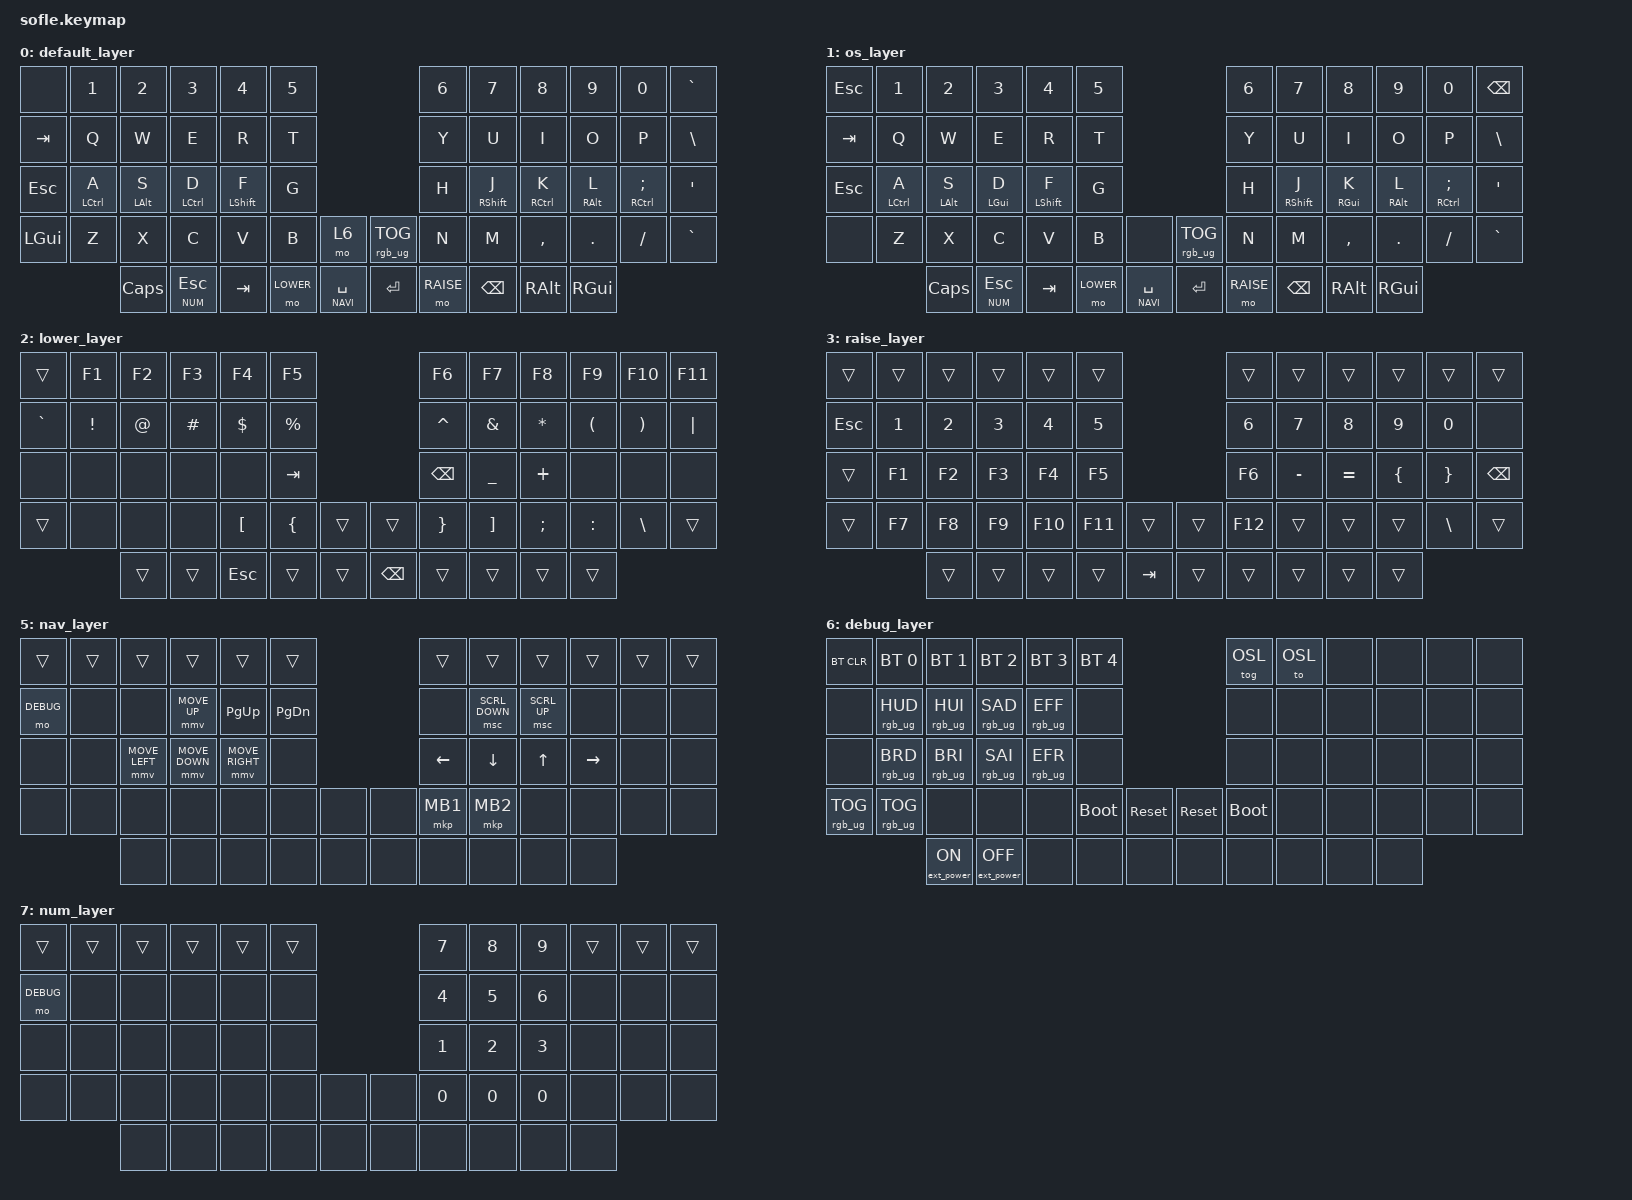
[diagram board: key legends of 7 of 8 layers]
/*
 * Copyright (c) 2020 The ZMK Contributors
 *
 * SPDX-License-Identifier: MIT
 */

#include "zmk-helpers/helper.h"

// Source desired key-position labels

#include "zmk-helpers/key-labels/sofle.h"

// tap windows for ctl alt and gui

#define HM_TAPPING_TERM 200
#define HM_TAPPING_REPEAT 210

// quick tapping for shift

#define HM_TAPPING_TERM_FAST 200
#define HM_PRIOR_IDLE 70
#define BASE 0
#define OSL 1
#define LOWER 2
#define RAISE 3
#define ADJUST 4
#define NAVI   5
#define DEBUG  6
#define NUM    7

// https://github.com/urob/zmk-config/tree/main#timeless-homerow-mods

#define KEYS_L LN5 LN4 LN3 LN2 LN1 LN0 LT0 LT1 LT2 LT3 LT4 LT5 LM0 LM1 LM2 LM3 LM4 LM5 LB0 LB1 LB2 LB3 LB4 LB5  // left hand
#define KEYS_R RN0 RN1 RN2 RN3 RN4 RN5 RT0 RT1 RT2 RT3 RT4 RT5 RM0 RM1 RM2 RM3 RM4 RM5 RB0 RB1 RB2 RB3 RB4 RB5  // right hand

#define THUMBS LH1 LH0 RH0 RH1
#define KEYS_T LH1 LH0 RH0 RH1

#include <behaviors.dtsi>
#include <dt-bindings/zmk/bt.h>
#include <dt-bindings/zmk/ext_power.h>
#include <dt-bindings/zmk/keys.h>
#include <dt-bindings/zmk/pointing.h>
#include <dt-bindings/zmk/pointing.h>
#include <dt-bindings/zmk/pointing.h>
#include <dt-bindings/zmk/rgb.h>

/ {
    // Activate ADJUST layer by pressing raise and lower

    behaviors {
        // Positional Homerow mods
        // Homerow mods that prevent accidental activations when rolling keys,
        // such as when typing `st` or `ne` on colemak-dh layouts or `as` on
        // qwerty.
        //
        // Works by only allowing a mod to activate within tapping-term if
        // it's on the opposite side of the keyboard or on the same side thumb
        // keys.
        // Further optimization using urob's timerless homerow mods method:
        // https://github.com/urob/zmk-config#timeless-homerow-mods

        hm_l: homerow_mods_left {
            compatible = "zmk,behavior-hold-tap";
            #binding-cells = <2>;
            bindings = <&kp>, <&kp>;

            flavor = "balanced";
            tapping-term-ms = <HM_TAPPING_TERM>;
            quick-tap-ms = <200>;                // repeat on tap-into-hold
            require-prior-idle-ms = <HM_PRIOR_IDLE>;
            hold-trigger-key-positions = <KEYS_R KEYS_T>;
            hold-trigger-on-release;
        };

        hm_r: homerow_mods_right {
            compatible = "zmk,behavior-hold-tap";
            #binding-cells = <2>;
            bindings = <&kp>, <&kp>;

            flavor = "balanced";
            tapping-term-ms = <HM_TAPPING_TERM>;
            quick-tap-ms = <200>;
            require-prior-idle-ms = <HM_PRIOR_IDLE>;
            hold-trigger-key-positions = <KEYS_L KEYS_T>;
            hold-trigger-on-release;
        };

        // Positional Homerow mods for shift
        // Use faster tapping term and disable some features that may
        // cause false negatives.

        hm_shift_l: hm_shift_l {
            compatible = "zmk,behavior-hold-tap";
            #binding-cells = <2>;
            bindings = <&kp>, <&kp>;

            //flavor = "balanced";

            flavor = "balanced";
            tapping-term-ms = <HM_TAPPING_TERM_FAST>;
            quick-tap-ms = <200>;
            require-prior-idle-ms = <HM_PRIOR_IDLE>;
            hold-trigger-key-positions = <KEYS_R KEYS_T>;
            hold-trigger-on-release;
        };

        hm_shift_r: hm_shift_r {
            compatible = "zmk,behavior-hold-tap";
            #binding-cells = <2>;
            bindings = <&kp>, <&kp>;

            flavor = "balanced";
            tapping-term-ms = <HM_TAPPING_TERM_FAST>;
            quick-tap-ms = <200>;
            require-prior-idle-ms = <HM_PRIOR_IDLE>;
            hold-trigger-key-positions = <KEYS_L KEYS_T>;

            // for quick tapping; shift+~

            hold-trigger-on-release;
        };

        /*
         * Non-Positional Homerow Mods
         * Used for &mm_grescm_gui behavior on left hand.
         *
         * Usage: &hm LSHFT T
         * Tap: T
         * Tap-Tap-Hold: Repeat T
         * Hold: LSHIFT
         */

        hm: homerow_mods {
            compatible = "zmk,behavior-hold-tap";
            #binding-cells = <2>;
            bindings = <&kp>, <&kp>;

            flavor = "balanced";
            tapping-term-ms = <HM_TAPPING_TERM>;
            quick-tap-ms = <200>;
        };
    };

    conditional_layers {
        compatible = "zmk,conditional-layers";

        adjust_layer {
            if-layers = <LOWER RAISE>;
            then-layer = <ADJUST>;
        };
    };

    keymap {
        compatible = "zmk,keymap";

        default_layer {
            // ------------------------------------------------------------------------------------------------------------
            // |   `   |  1  |  2  |  3   |  4   |  5   |                   |  6   |  7    |  8    |  9   |   0   |       |
            // |  ESC  |  Q  |  W  |  E   |  R   |  T   |                   |  Y   |  U    |  I    |  O   |   P   | BKSPC |
            // |  TAB  |  A  |  S  |  D   |  F   |  G   |                   |  H   |  J    |  K    |  L   |   ;   |   '   |
            // | SHIFT |  Z  |  X  |  C   |  V   |  B   |  MUTE  |  |       |  N   |  M    |  ,    |  .   |   /   | SHIFT |
            //               | GUI | ALT  | CTRL | LOWER|  ENTER |  | SPACE | RAISE| CTRL  | ALT   | GUI  |

            bindings = <
&none     &kp N1         &kp N2        &kp N3         &kp N4               &kp N5                                        &kp N6     &kp N7               &kp N8         &kp N9        &kp N0            &kp GRAVE
&kp TAB   &kp Q          &kp W         &kp E          &kp R                &kp T                                         &kp Y      &kp U                &kp I          &kp O         &kp P             &kp BSLH
&kp ESC   &hm_l LCTRL A  &hm_l LALT S  &hm_l LCTRL D  &hm_shift_l LSHFT F  &kp G                                         &kp H      &hm_shift_r RSHFT J  &hm_r RCTRL K  &hm_r RALT L  &hm_r RCTRL SEMI  &kp SQT
&kp LGUI  &kp Z          &kp X         &kp C          &kp V                &kp B      &mo 6             &rgb_ug RGB_TOG  &kp N      &kp M                &kp COMMA      &kp DOT       &kp FSLH          &kp GRAVE
                         &kp CAPS      &lt NUM ESC    &kp TAB              &mo LOWER  &lt NAVI SPACE    &kp RET          &mo RAISE  &kp BSPC             &kp RALT       &kp RGUI
            >;

            sensor-bindings = <&inc_dec_kp C_VOL_UP C_VOL_DN &inc_dec_kp PG_UP PG_DN>;
        };

        os_layer {
            // ------------------------------------------------------------------------------------------------------------
            // |   `   |  1  |  2  |  3   |  4   |  5   |                   |  6   |  7    |  8    |  9   |   0   |       |
            // |  ESC  |  Q  |  W  |  E   |  R   |  T   |                   |  Y   |  U    |  I    |  O   |   P   | BKSPC |
            // |  TAB  |  A  |  S  |  D   |  F   |  G   |                   |  H   |  J    |  K    |  L   |   ;   |   '   |
            // | SHIFT |  Z  |  X  |  C   |  V   |  B   |  MUTE  |  |       |  N   |  M    |  ,    |  .   |   /   | SHIFT |
            //               | GUI | ALT  | CTRL | LOWER|  ENTER |  | SPACE | RAISE| CTRL  | ALT   | GUI  |

            bindings = <
&kp ESC  &kp N1         &kp N2        &kp N3        &kp N4               &kp N5                                        &kp N6     &kp N7               &kp N8        &kp N9        &kp N0            &kp BSPC
&kp TAB  &kp Q          &kp W         &kp E         &kp R                &kp T                                         &kp Y      &kp U                &kp I         &kp O         &kp P             &kp BSLH
&kp ESC  &hm_l LCTRL A  &hm_l LALT S  &hm_l LGUI D  &hm_shift_l LSHFT F  &kp G                                         &kp H      &hm_shift_r RSHFT J  &hm_r RGUI K  &hm_r RALT L  &hm_r RCTRL SEMI  &kp SQT
&none    &kp Z          &kp X         &kp C         &kp V                &kp B      &none             &rgb_ug RGB_TOG  &kp N      &kp M                &kp COMMA     &kp DOT       &kp FSLH          &kp GRAVE
                        &kp CAPS      &lt NUM ESC   &kp TAB              &mo LOWER  &lt NAVI SPACE    &kp RET          &mo RAISE  &kp BSPC             &kp RALT      &kp RGUI
            >;

            sensor-bindings = <&inc_dec_kp C_VOL_UP C_VOL_DN &inc_dec_kp PG_UP PG_DN>;
        };

        lower_layer {
            // TODO: Some binds are waiting for shifted keycode support.
            // -------------------------------
            // |       |  F1 |  F2 |  F3  |  F4  |  F5  |                   |  F6  |  F7   |  F8   |  F9  |  F10  |  F11  |
            // |   `   |  1  |  2  |  3   |  4   |  5   |                   |  6   |  7    |  8    |  9   |   0   |  F12  |
            // |       |  !  |  @  |  #   |  $   |  %   |                   |  ^   |  &    |  *    |  (   |   )   |   |   |
            // |       |  =  |  -  |  +   |  {   |  }   |        |  |       |  [   |  ]    |  ;    |  :   |   \   |       |
            //               |     |      |      |      |        |  |       |      |       |       |      |

            bindings = <
&trans     &kp F1    &kp F2  &kp F3    &kp F4            &kp F5                         &kp F6           &kp F7     &kp F8     &kp F9     &kp F10   &kp F11
&kp GRAVE  &kp EXCL  &kp AT  &kp HASH  &kp DLLR          &kp PRCNT                      &kp CARET        &kp AMPS   &kp ASTRK  &kp LPAR   &kp RPAR  &kp PIPE
&none      &none     &none   &none     &none             &kp TAB                        &kp BSPC         &kp UNDER  &kp PLUS   &none      &none     &none
&trans     &none     &none   &none     &kp LEFT_BRACKET  &kp LBRC   &trans    &trans    &kp RIGHT_BRACE  &kp RBKT   &kp SEMI   &kp COLON  &kp BSLH  &trans
                     &trans  &trans    &kp ESC           &trans     &trans    &kp BSPC  &trans           &trans     &trans     &trans
            >;

            sensor-bindings = <&inc_dec_kp C_VOL_UP C_VOL_DN &inc_dec_kp PG_UP PG_DN>;
        };

        raise_layer {
            // ------------------------------------------------------------------------------------------------------------
            // | BTCLR | BT1  | BT2  |  BT3  |  BT4  |  BT5 |                |      |      |       |      |       |       |
            // |       | INS  | PSCR | GUI   |       |      |                | PGUP |      |   ^   |      |       |       |
            // |       | ALT  | CTRL | SHIFT |       | CAPS |                | PGDN |   <- |   v   |  ->  |  DEL  | BKSPC |
            // |       | UNDO | CUT  | COPY  | PASTE |      |      |  |      |      |      |       |      |       |       |
            //                |      |       |       |      |      |  |      |      |      |       |      |

            bindings = <
&trans   &trans  &trans  &trans  &trans   &trans                     &trans   &trans     &trans     &trans    &trans    &trans
&kp ESC  &kp N1  &kp N2  &kp N3  &kp N4   &kp N5                     &kp N6   &kp N7     &kp N8     &kp N9    &kp N0    &none
&trans   &kp F1  &kp F2  &kp F3  &kp F4   &kp F5                     &kp F6   &kp MINUS  &kp EQUAL  &kp LBRC  &kp RBRC  &kp BSPC
&trans   &kp F7  &kp F8  &kp F9  &kp F10  &kp F11  &trans    &trans  &kp F12  &trans     &trans     &trans    &kp BSLH  &trans
                 &trans  &trans  &trans   &trans   &kp TAB   &trans  &trans   &trans     &trans     &trans
            >;

            sensor-bindings = <&inc_dec_kp C_VOL_UP C_VOL_DN &inc_dec_kp PG_UP PG_DN>;
        };

        adjust_layer {
            // ----------------------------------------------------------------------------------------------------------------------------
            // | BTCLR  |  BT1    |  BT2    |   BT3   |   BT4   |   BT5   |                  |      |      |       |      |       |       |
            // | moDEBUG| RGB_HUD | RGB_HUI | RGB_SAD | RGB_SAI | RGB_EFF |                  |      |      |       |      |       |       |
            // | EXTPWR | RGB_BRD | RGB_BRI |         |         |         |                  |      |      |       |      |       |       |
            // |        |         |         |         |         |         | RGB_TOG | |      |      |      |       |      |       |       |
            //                    |         |         |         |         |         | |      |      |      |       |      |

            bindings = <
&none            &bt BT_SEL 0     &bt BT_SEL 1       &bt BT_SEL 2     &bt BT_SEL 3  &bt BT_SEL 4                       &tog OSL  &to OSL  &none  &none  &none  &tog OSL
&rgb_ug RGB_HUD  &rgb_ug RGB_HUI  &rgb_ug RGB_SAD    &rgb_ug RGB_EFF  &none         &none                              &none     &none    &none  &none  &none  &none
&rgb_ug RGB_BRD  &rgb_ug RGB_BRI  &rgb_ug RGB_SAI    &rgb_ug RGB_EFR  &none         &none                              &none     &none    &none  &none  &none  &rgb_ug RGB_TOG
&none            &none            &none              &none            &none         &sys_reset    &sys_reset    &none  &none     &none    &none  &none  &none  &ext_power EP_ON
                                  &ext_power EP_OFF  &none            &none         &none         &none         &none  &none     &none    &none
            >;
        };

        nav_layer {
            // ----------------------------------------------------------------------------------------------------------------------------
            // | BTCLR  |  BT1    |  BT2    |   BT3   |   BT4   |   BT5   |                  |      |      |       |      |       |       |
            // | moDEBUG| RGB_HUD | RGB_HUI | RGB_SAD | RGB_SAI | RGB_EFF |                  |      |      |       |      |       |       |
            // | EXTPWR | RGB_BRD | RGB_BRI |         |         |         |                  |      |      |       |      |       |       |
            // |        |         |         |         |         |         | RGB_TOG | |      |      |      |       |      |       |       |
            //                    |         |         |         |         |         | |      |      |      |       |      |

            bindings = <
&trans     &trans  &trans          &trans          &trans           &trans                         &trans    &trans          &trans        &trans     &trans  &trans
&mo DEBUG  &none   &none           &mmv MOVE_UP    &kp PAGE_UP      &kp PAGE_DOWN                  &none     &msc SCRL_DOWN  &msc SCRL_UP  &none      &none   &none
&none      &none   &mmv MOVE_LEFT  &mmv MOVE_DOWN  &mmv MOVE_RIGHT  &none                          &kp LEFT  &kp DOWN        &kp UP        &kp RIGHT  &none   &none
&none      &none   &none           &none           &none            &none          &none    &none  &mkp MB1  &mkp MB2        &none         &none      &none   &none
                   &none           &none           &none            &none          &none    &none  &none     &none           &none         &none
            >;
        };

        debug_layer {
            // ----------------------------------------------------------------------------------------------------------------------------
            // | BTCLR  |  BT1    |  BT2    |   BT3   |   BT4   |   BT5   |                  |      |      |       |      |       |       |
            // | EXTPWR | RGB_HUD | RGB_HUI | RGB_SAD | RGB_SAI | RGB_EFF |                  |      |      |       |      |       |       |
            // |        | RGB_BRD | RGB_BRI |         |         |         |                  |      |      |       |      |       |       |
            // |        |         |         |         |         |         | RGB_TOG | |      |      |      |       |      |       |       |
            //                    |         |         |         |         |         | |      |      |      |       |      |

            bindings = <
&bt BT_CLR       &bt BT_SEL 0     &bt BT_SEL 1      &bt BT_SEL 2       &bt BT_SEL 3     &bt BT_SEL 4                            &tog OSL     &to OSL  &none  &none  &none  &none
&none            &rgb_ug RGB_HUD  &rgb_ug RGB_HUI   &rgb_ug RGB_SAD    &rgb_ug RGB_EFF  &none                                   &none        &none    &none  &none  &none  &none
&none            &rgb_ug RGB_BRD  &rgb_ug RGB_BRI   &rgb_ug RGB_SAI    &rgb_ug RGB_EFR  &none                                   &none        &none    &none  &none  &none  &none
&rgb_ug RGB_TOG  &rgb_ug RGB_TOG  &none             &none              &none            &bootloader   &sys_reset    &sys_reset  &bootloader  &none    &none  &none  &none  &none
                                  &ext_power EP_ON  &ext_power EP_OFF  &none            &none         &none         &none       &none        &none    &none  &none
            >;
        };

        num_layer {
            // ----------------------------------------------------------------------------------------------------------------------------
            // | BTCLR  |  BT1    |  BT2    |   BT3   |   BT4   |   BT5   |                  |      |      |       |      |       |       |
            // | moDEBUG| RGB_HUD | RGB_HUI | RGB_SAD | RGB_SAI | RGB_EFF |                  |      |      |       |      |       |       |
            // | EXTPWR | RGB_BRD | RGB_BRI |         |         |         |                  |      |      |       |      |       |       |
            // |        |         |         |         |         |         | RGB_TOG | |      |      |      |       |      |       |       |
            //                    |         |         |         |         |         | |      |      |      |       |      |

            bindings = <
&trans     &trans  &trans  &trans  &trans  &trans                  &kp N7  &kp N8  &kp N9  &trans  &trans  &trans
&mo DEBUG  &none   &none   &none   &none   &none                   &kp N4  &kp N5  &kp N6  &none   &none   &none
&none      &none   &none   &none   &none   &none                   &kp N1  &kp N2  &kp N3  &none   &none   &none
&none      &none   &none   &none   &none   &none   &none    &none  &kp N0  &kp N0  &kp N0  &none   &none   &none
                   &none   &none   &none   &none   &none    &none  &none   &none   &none   &none
            >;
        };

        extra1 { status = "reserved"; };

        extra2 { status = "reserved"; };

        extra3 { status = "reserved"; };

        extra4 { status = "reserved"; };
    };
};
